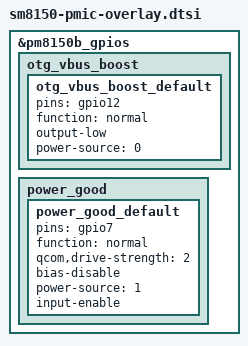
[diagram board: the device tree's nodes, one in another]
#include "../../../sm8150-pmic-overlay.dtsi"

#include "pm8150.dtsi"
#include "pm8150b.dtsi"
#include "pm8150l.dtsi"

&pm8150b_gpios {
    otg_vbus_boost {
		otg_vbus_boost_default: otg_vbus_boost_default {
			pins = "gpio12";
			function = "normal";
			output-low;
			power-source = <0>;
		};
	};

	power_good {
		/*Get the DC Power Good signal*/
		power_good_default: power_good_default {
			pins = "gpio7";
			function = "normal";
			qcom,drive-strength = <2>; /* 2 MA */
			bias-disable;         /* NO pull */
			power-source = <1>;
			input-enable;
		};
	};
};
